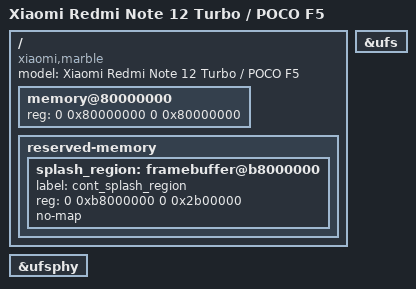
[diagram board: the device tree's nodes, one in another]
// SPDX-License-Identifier: BSD-2-Clause-Patent
/dts-v1/;
/include/ "sm7475.dtsi"

/ {
    model = "Xiaomi Redmi Note 12 Turbo / POCO F5";
    compatible = "xiaomi,marble", "qcom,sm7475";

    // DRAM below 4 GiB: 0x80000000-0xffffffff (the 10 GB total continues at 0x800000000).
    memory@80000000 {
        device_type = "memory";
        reg = <0 0x80000000 0 0x80000000>;
    };

    reserved-memory {
        #address-cells = <2>;
        #size-cells = <2>;
        ranges;
        // "Display Reserved" in uefi-marble's MemoryMapLib.c
        splash_region: framebuffer@b8000000 {
            label = "cont_splash_region";
            reg = <0 0xb8000000 0 0x2b00000>;
            no-map;
        };
    };
};

// E/P cluster tags stay off until the AMP and Edge scheduler patches are in the SoC feed (marble-pmos facts: 4x A510, 3x A710, 1x X2).
&ufs { status = "okay"; };
&ufsphy { status = "okay"; };
